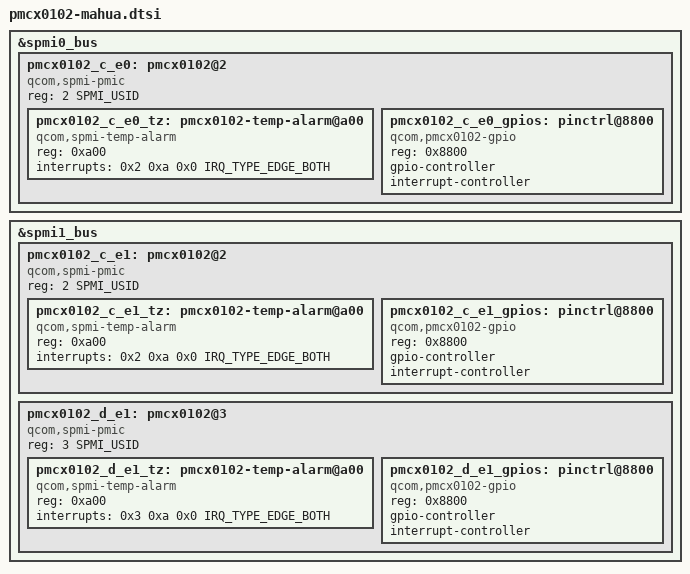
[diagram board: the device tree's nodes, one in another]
// SPDX-License-Identifier: BSD-3-Clause
/*
 * Copyright (c) Qualcomm Technologies, Inc. and/or its subsidiaries.
 */

#include <dt-bindings/interrupt-controller/irq.h>
#include <dt-bindings/spmi/spmi.h>

&spmi0_bus {
	pmcx0102_c_e0: pmcx0102@2 {
		compatible = "qcom,spmi-pmic";
		reg = <2 SPMI_USID>;
		#address-cells = <1>;
		#size-cells = <0>;

		pmcx0102_c_e0_tz: pmcx0102-temp-alarm@a00 {
			compatible = "qcom,spmi-temp-alarm";
			reg = <0xa00>;
			interrupts = <0x2 0xa 0x0 IRQ_TYPE_EDGE_BOTH>;
			#thermal-sensor-cells = <0>;
		};

		pmcx0102_c_e0_gpios: pinctrl@8800 {
			compatible = "qcom,pmcx0102-gpio";
			reg = <0x8800>;
			gpio-controller;
			#gpio-cells = <2>;
			interrupt-controller;
			#interrupt-cells = <2>;
		};
	};
};

&spmi1_bus {
	pmcx0102_c_e1: pmcx0102@2 {
		compatible = "qcom,spmi-pmic";
		reg = <2 SPMI_USID>;
		#address-cells = <1>;
		#size-cells = <0>;

		pmcx0102_c_e1_tz: pmcx0102-temp-alarm@a00 {
			compatible = "qcom,spmi-temp-alarm";
			reg = <0xa00>;
			interrupts = <0x2 0xa 0x0 IRQ_TYPE_EDGE_BOTH>;
			#thermal-sensor-cells = <0>;
		};

		pmcx0102_c_e1_gpios: pinctrl@8800 {
			compatible = "qcom,pmcx0102-gpio";
			reg = <0x8800>;
			gpio-controller;
			#gpio-cells = <2>;
			interrupt-controller;
			#interrupt-cells = <2>;
		};
	};

	pmcx0102_d_e1: pmcx0102@3 {
		compatible = "qcom,spmi-pmic";
		reg = <3 SPMI_USID>;
		#address-cells = <1>;
		#size-cells = <0>;

		pmcx0102_d_e1_tz: pmcx0102-temp-alarm@a00 {
			compatible = "qcom,spmi-temp-alarm";
			reg = <0xa00>;
			interrupts = <0x3 0xa 0x0 IRQ_TYPE_EDGE_BOTH>;
			#thermal-sensor-cells = <0>;
		};

		pmcx0102_d_e1_gpios: pinctrl@8800 {
			compatible = "qcom,pmcx0102-gpio";
			reg = <0x8800>;
			gpio-controller;
			#gpio-cells = <2>;
			interrupt-controller;
			#interrupt-cells = <2>;
		};
	};
};
